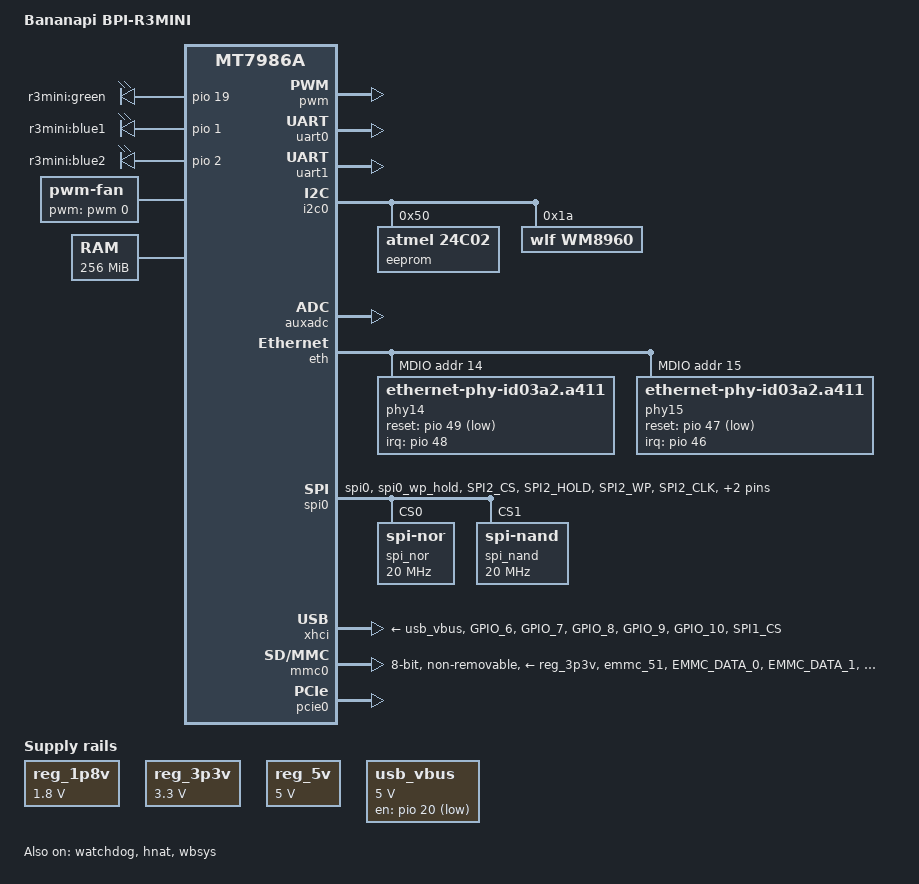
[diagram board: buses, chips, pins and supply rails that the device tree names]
/dts-v1/;
#include "mt7986a.dtsi"
#include "mt7986a-pinctrl.dtsi"
#include "mt7986-spim-nand-partition-bpir3_mini.dtsi"
#include <dt-bindings/input/input.h>
#include <dt-bindings/gpio/gpio.h>
/ {
	model = "Bananapi BPI-R3MINI";
	compatible = "bananapi,bpi-r3mini", "mediatek,mt7986a";
	
	aliases {
		led-boot = &status_led;
		led-failsafe = &status_led;
		led-running = &status_led;
		led-upgrade = &status_led;
	};
	
	leds {
		compatible = "gpio-leds";

		status_led: green {
			label = "r3mini:green";
			gpios = <&pio 19 GPIO_ACTIVE_HIGH>;
		};

		led-1 {
			label = "r3mini:blue1";
			gpios = <&pio 1 GPIO_ACTIVE_HIGH>;
			default-state = "on";
		};

		led-2 {
			label = "r3mini:blue2";
			gpios = <&pio 2 GPIO_ACTIVE_HIGH>;
			default-state = "on";
		};
	};

	fan: pwm-fan {
		compatible = "pwm-fan";
		#cooling-cells = <2>;
		cooling-levels = <255 128 80 0>;
		pwms = <&pwm 0 10000 0>;
		status = "okay";
	};
	
	
	chosen {
		bootargs = "console=ttyS0,115200n1 loglevel=8  \
				earlycon=uart8250,mmio32,0x11002000";
	};

	memory {
		reg = <0 0x40000000 0 0x10000000>;
	};

	reg_1p8v: regulator-1p8v {
			compatible = "regulator-fixed";
			regulator-name = "fixed-1.8V";
			regulator-min-microvolt = <1800000>;
			regulator-max-microvolt = <1800000>;
			regulator-boot-on;
			regulator-always-on;
	};

	reg_3p3v: regulator-3p3v {
			compatible = "regulator-fixed";
			regulator-name = "fixed-3.3V";
			regulator-min-microvolt = <3300000>;
			regulator-max-microvolt = <3300000>;
			regulator-boot-on;
			regulator-always-on;
	};

	reg_5v: regulator-5v {
		compatible = "regulator-fixed";
		regulator-name = "fixed-5V";
		regulator-min-microvolt = <5000000>;
		regulator-max-microvolt = <5000000>;
		regulator-boot-on;
		regulator-always-on;
	};

	usb_vbus: regulator-usb-vbus {
		compatible = "regulator-fixed";
		regulator-name = "usb_vbus";
		regulator-min-microvolt = <5000000>;
		regulator-max-microvolt = <5000000>;
		gpios = <&pio 20 GPIO_ACTIVE_LOW>;
		regulator-boot-on;
	};

	sound {
		compatible = "mediatek,mt7986-wm8960-machine";
		mediatek,platform = <&afe>;
		audio-routing = "Headphone", "HP_L",
				"Headphone", "HP_R",
				"LINPUT1", "AMIC",
				"RINPUT1", "AMIC";
		mediatek,audio-codec = <&wm8960>;
		status = "okay";
	};
};

&pwm {
	pinctrl-names = "default";
	pinctrl-0 = <&pwm0_pin &pwm1_pin_g1>;
	status = "okay";
};

&uart0 {
	status = "okay";
};

&uart1 {
	pinctrl-names = "default";
	pinctrl-0 = <&uart1_pins>;
	status = "okay";
};

&uart2 {
	pinctrl-names = "default";
	pinctrl-0 = <&uart2_pins>;
	status = "disabled";
};

&i2c0 {
	pinctrl-names = "default";
	pinctrl-0 = <&i2c_pins>;
	status = "okay";

	/* MAC Address EEPROM */
        eeprom@50 {
                compatible = "atmel,24c02";
                reg = <0x50>;

                address-bits = <8>;
                page-size = <8>;
                size = <256>;
        }; 

	wm8960: wm8960@1a {
		compatible = "wlf,wm8960";
		reg = <0x1a>;
	};
};

&auxadc {
	status = "okay";
};

&watchdog {
	status = "okay";
};

&eth {
	status = "okay";

	gmac0: mac@0 {
		compatible = "mediatek,eth-mac";
		reg = <0>;
		phy-mode = "2500base-x";
		
		fixed-link {
			speed = <2500>;
			full-duplex;
			pause;
		};
	};

	gmac1: mac@1 {
		label = "wan";
		compatible = "mediatek,eth-mac";
		reg = <1>;
		phy-mode = "2500base-x";
		
		fixed-link {
			speed = <2500>;
			full-duplex;
			pause;
		}; 
	};

	mdio: mdio-bus {
		#address-cells = <1>;
		#size-cells = <0>;

		phy14: phy@14 {
			compatible = "ethernet-phy-id03a2.a411";
			reg = <14>;
			pinctrl-names = "default";
			pinctrl-0 = <&en8811_pwr_a>;

			airoha,polarity = <3>;

			interrupt-parent = <&pio>;
			interrupts = <48 IRQ_TYPE_LEVEL_HIGH>;
			reset-gpios = <&pio 49 1>;
			reset-assert-us = <10000>;
			reset-deassert-us = <20000>;

			phy-mode = "2500base-x";
			full-duplex;
			pause;
		};

		phy15: phy@15 {
			compatible = "ethernet-phy-id03a2.a411";
			reg = <15>;
			pinctrl-names = "default";
			pinctrl-0 = <&en8811_pwr_b>;

			airoha,polarity = <3>;

			interrupt-parent = <&pio>;
			interrupts = <46 IRQ_TYPE_LEVEL_HIGH>;
			reset-gpios = <&pio 47 1>;
			reset-assert-us = <10000>;
			reset-deassert-us = <20000>;

			phy-mode = "2500base-x";
			full-duplex;
			pause;
		};
	};
};

&cpu_thermal {
	trips {
		cpu_trip_critical: critical {
			temperature = <85000>;
			hysteresis = <2000>;
			type = "critical";
		};

		cpu_trip_hot: hot {
			temperature = <65000>;
			hysteresis = <2000>;
			type = "hot";
		};

		cpu_trip_active: active {
			temperature = <50000>;
			hysteresis = <2000>;
			type = "active";
		};

		cpu_trip_passive: passive {
			temperature = <40000>;
			hysteresis = <2000>;
			type = "passive";
		};
	};

	cooling-maps {
		cpu-active-high {
			cooling-device = <&fan 3 3>;
			trip = <&cpu_trip_critical>;
		};

		cpu-active-low {
			cooling-device = <&fan 2 2>;
			trip = <&cpu_trip_hot>;
		};

		cpu-active {
			cooling-device = <&fan 1 1>;
			trip = <&cpu_trip_active>;
		};

		cpu-passive {
			cooling-device = <&fan 0 0>;
			trip = <&cpu_trip_passive>;
		};
	};
};

&hnat {
	mtketh-wan = "eth1";
	mtketh-lan = "eth0";
	mtketh-max-gmac = <2>;
	ext-devices-prefix = "usb", "wwan","rmnet","eth3","eth4","eth5";
	status = "okay";
};

&spi0 {
	pinctrl-names = "default";
	pinctrl-0 = <&spi_flash_pins>;
	cs-gpios = <0>, <0>;
	status = "okay";

	spi_nor@0 {
		#address-cells = <1>;
		#size-cells = <1>;
		compatible = "jedec,spi-nor";
		reg = <0>;
		spi-max-frequency = <20000000>;
		spi-tx-buswidth = <4>;
		spi-rx-buswidth = <4>;
	};

	spi_nand: spi_nand@1 {
		#address-cells = <1>;
		#size-cells = <1>;
		compatible = "spi-nand";
		reg = <1>;
		spi-max-frequency = <20000000>;
		spi-tx-buswidth = <4>;
		spi-rx-buswidth = <4>;
	};
};

&spi1 {
	pinctrl-names = "default";
	pinctrl-0 = <&spic_pins_g2>;
	status = "disabled";
};

/* Add usb pin control  */
&xhci {
	pinctrl-names = "default";
	pinctrl-0 = <&usb_ngff_pins>;
	vusb33-supply = <&reg_3p3v>;
	vbus-supply = <&usb_vbus>;
	status = "okay";
};

&mmc0 {
        pinctrl-names = "default", "state_uhs";
        pinctrl-0 = <&mmc0_pins_default>;
        pinctrl-1 = <&mmc0_pins_uhs>;
        bus-width = <8>;
        max-frequency = <200000000>;
        cap-mmc-highspeed;
        mmc-hs200-1_8v;
        mmc-hs400-1_8v;
        hs400-ds-delay = <0x14014>;
        vmmc-supply = <&reg_3p3v>;
        vqmmc-supply = <&reg_1p8v>;
        non-removable;
        no-sd;
        no-sdio;
        status = "okay";
};

&pcie0 {
	pinctrl-names = "default";
	pinctrl-0 = <&pcie0_pins>;
	status = "okay";
};

&wbsys {
	mediatek,mtd-eeprom = <&factory 0x0000>;
	status = "okay";
	pinctrl-names = "default", "dbdc";
	pinctrl-0 = <&wf_2g_5g_pins>;
	pinctrl-1 = <&wf_dbdc_pins>;
};

&pio {
/* Define usb_ngff_pins SPI1_CS --> GPIO 32 */

	usb_ngff_pins: usb-ngff-pins {
		ngff-gnss-off {
			pins = "GPIO_6";
			drive-strength = <8>;
			mediatek,pull-up-adv = <1>;
		};
		ngff-pe-rst {
			pins = "GPIO_7";
			drive-strength = <8>;
			mediatek,pull-up-adv = <1>;
		};
		ngff-wwan-off {
			pins = "GPIO_8";
			drive-strength = <8>;
			mediatek,pull-up-adv = <1>;
		};
		ngff-pwr-off {
			pins = "GPIO_9";
			drive-strength = <8>;
			mediatek,pull-up-adv = <1>;
		};
		ngff-rst {
			pins = "GPIO_10";
			drive-strength = <8>;
			mediatek,pull-up-adv = <1>;
		};
		ngff-coex {
			pins = "SPI1_CS";
			drive-strength = <8>;
			mediatek,pull-up-adv = <1>;
		};
	};

	 en8811_pwr_a: en8811-pwr-a {
                pins = "GPIO_11";
                drive-strength = <8>;
                mediatek,pull-down-adv = <1>;
                output-low;
        };

        en8811_pwr_b: en8811-pwr-b {
                pins = "GPIO_12";
                drive-strength = <8>;
                mediatek,pull-down-adv = <1>;
                output-low;
        };


        mmc0_pins_default: mmc0-pins-50-to-61-default {
                mux {
                        function = "flash";
                        groups = "emmc_51";
                };
                conf-cmd-dat {
                        pins = "EMMC_DATA_0", "EMMC_DATA_1", "EMMC_DATA_2",
                               "EMMC_DATA_3", "EMMC_DATA_4", "EMMC_DATA_5",
                               "EMMC_DATA_6", "EMMC_DATA_7", "EMMC_CMD";
                        input-enable;
                        drive-strength = <MTK_DRIVE_4mA>;
                        mediatek,pull-up-adv = <1>;     /* pull-up 10K */
                };
                conf-clk {
                        pins = "EMMC_CK";
                        drive-strength = <MTK_DRIVE_6mA>;
                        mediatek,pull-down-adv = <2>;   /* pull-down 50K */
                };
                conf-ds {
                        pins = "EMMC_DSL";
                        mediatek,pull-down-adv = <2>;   /* pull-down 50K */
                };
                conf-rst {
                        pins = "EMMC_RSTB";
                        drive-strength = <MTK_DRIVE_4mA>;
                        mediatek,pull-up-adv = <1>;     /* pull-up 10K */
                };
        };

        mmc0_pins_uhs: mmc0-pins-50-to-61-uhs {
                mux {
                        function = "flash";
                        groups = "emmc_51";
                };
                conf-cmd-dat {
                        pins = "EMMC_DATA_0", "EMMC_DATA_1", "EMMC_DATA_2",
                               "EMMC_DATA_3", "EMMC_DATA_4", "EMMC_DATA_5",
                               "EMMC_DATA_6", "EMMC_DATA_7", "EMMC_CMD";
                        input-enable;
                        drive-strength = <MTK_DRIVE_4mA>;
                        mediatek,pull-up-adv = <1>;     /* pull-up 10K */
                };
                conf-clk {
                        pins = "EMMC_CK";
                        drive-strength = <MTK_DRIVE_6mA>;
                        mediatek,pull-down-adv = <2>;   /* pull-down 50K */
                };
                conf-ds {
                        pins = "EMMC_DSL";
                        mediatek,pull-down-adv = <2>;   /* pull-down 50K */
                };
                conf-rst {
                        pins = "EMMC_RSTB";
                        drive-strength = <MTK_DRIVE_4mA>;
                        mediatek,pull-up-adv = <1>;     /* pull-up 10K */
                };
        };

	spi_flash_pins: spi-flash-pins-33-to-38 {
		mux {
			function = "flash";
			groups = "spi0", "spi0_wp_hold";
		};
		conf-pu {
			pins = "SPI2_CS", "SPI2_HOLD", "SPI2_WP";
			drive-strength = <MTK_DRIVE_8mA>;
			mediatek,pull-up-adv = <0>;	/* bias-disable */
		};
		conf-pd {
			pins = "SPI2_CLK", "SPI2_MOSI", "SPI2_MISO";
			drive-strength = <MTK_DRIVE_8mA>;
			mediatek,pull-down-adv = <0>;	/* bias-disable */
		};
	};

	wf_2g_5g_pins: wf_2g_5g-pins {
		mux {
			function = "wifi";
			groups = "wf_2g", "wf_5g";
		};
		conf {
			pins = "WF0_HB1", "WF0_HB2", "WF0_HB3", "WF0_HB4",
			       "WF0_HB0", "WF0_HB0_B", "WF0_HB5", "WF0_HB6",
			       "WF0_HB7", "WF0_HB8", "WF0_HB9", "WF0_HB10",
			       "WF0_TOP_CLK", "WF0_TOP_DATA", "WF1_HB1",
			       "WF1_HB2", "WF1_HB3", "WF1_HB4", "WF1_HB0",
			       "WF1_HB5", "WF1_HB6", "WF1_HB7", "WF1_HB8",
			       "WF1_TOP_CLK", "WF1_TOP_DATA";
			drive-strength = <MTK_DRIVE_4mA>;
		};
	};

	wf_dbdc_pins: wf_dbdc-pins {
		mux {
			function = "wifi";
			groups = "wf_dbdc";
		};
		conf {
			pins = "WF0_HB1", "WF0_HB2", "WF0_HB3", "WF0_HB4",
			       "WF0_HB0", "WF0_HB0_B", "WF0_HB5", "WF0_HB6",
			       "WF0_HB7", "WF0_HB8", "WF0_HB9", "WF0_HB10",
			       "WF0_TOP_CLK", "WF0_TOP_DATA", "WF1_HB1",
			       "WF1_HB2", "WF1_HB3", "WF1_HB4", "WF1_HB0",
			       "WF1_HB5", "WF1_HB6", "WF1_HB7", "WF1_HB8",
			       "WF1_TOP_CLK", "WF1_TOP_DATA";
			drive-strength = <MTK_DRIVE_4mA>;
		};
	};
};
